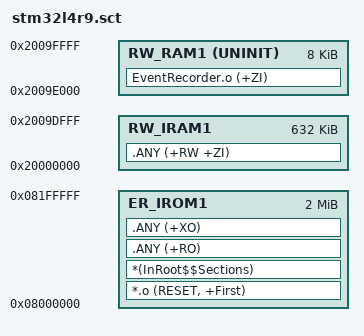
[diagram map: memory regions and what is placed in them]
; *************************************************************
; *** Scatter-Loading Description File generated by uVision ***
; *************************************************************

LR_IROM1 0x08000000 0x00200000  {    ; load region size_region
  ER_IROM1 0x08000000 0x00200000  {  ; load address = execution address
   *.o (RESET, +First)
   *(InRoot$$Sections)
   .ANY (+RO)
   .ANY (+XO)
  }
  RW_IRAM1 0x20000000 0x0009E000  {  ; RW data (SRAM1 + SRAM2 + SRAM3)
   .ANY (+RW +ZI)
  }
  RW_RAM1 0x2009E000 UNINIT 0x00002000  {
    EventRecorder.o (+ZI)
  }
}
